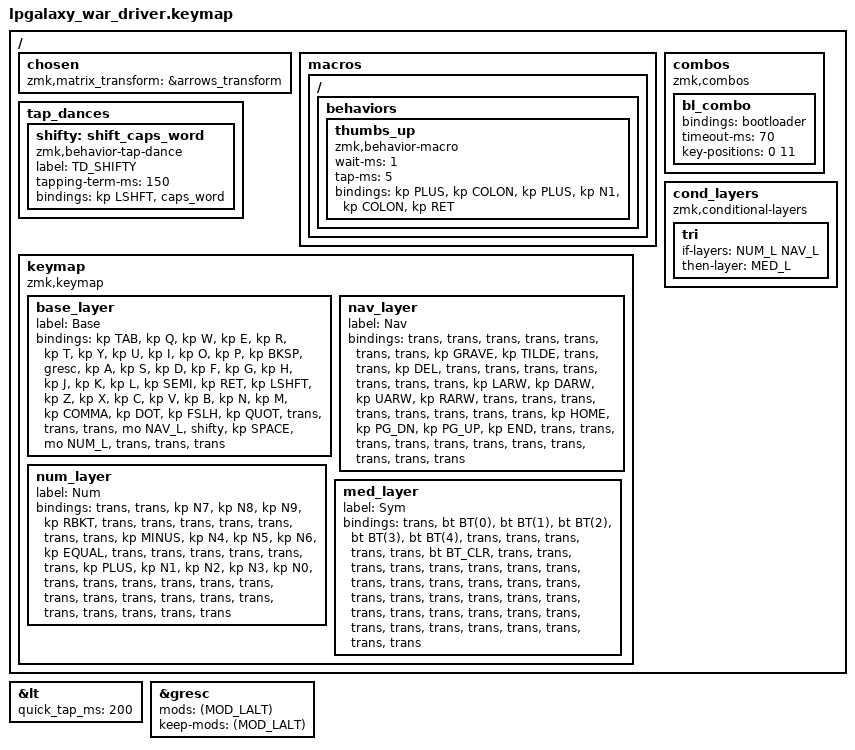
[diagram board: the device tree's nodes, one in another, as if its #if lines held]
/*
 * Copyright (c) 2022 Pete Johanson
 *
 * SPDX-License-Identifier: MIT
 */

#include <behaviors.dtsi>
#include <dt-bindings/zmk/keys.h>
#include <dt-bindings/zmk/bt.h>
#include <dt-bindings/zmk/outputs.h>

// #define QWERTY_BASE 1

#define LAYOUT_STD   1
// #define LAYOUT_ARROWS     1
// #define LAYOUT_SOUTHPAW 1

#define NAV_L 1
#define NUM_L 2
#define MED_L 3

// Using layer taps on thumbs, having quick tap as well helps w/ repeating space/backspace
&lt { quick_tap_ms = <200>; };

#define BT(n) BT_SEL n

&gresc {
    mods = <(MOD_LALT)>;
    keep-mods = <(MOD_LALT)>;
};

/ {
    chosen {
       zmk,matrix_transform =
#ifdef LAYOUT_ARROWS
                       &arrows_transform;
#elif defined(LAYOUT_SOUTHPAW)
                       &southpaw_transform;
#else
                       &standard_transform;
#endif
    };

    macros {
      ZMK_MACRO(thumbs_up,
		wait-ms = <1>;
		tap-ms = <5>;
                bindings = <&kp PLUS &kp COLON &kp PLUS &kp N1 &kp COLON &kp RET>;
		)
    };
    
    tap_dances {
    	shifty: shift_caps_word {
		compatible = "zmk,behavior-tap-dance";
		label = "TD_SHIFTY";
		#binding-cells = <0>;
		tapping-term-ms = <150>;
		bindings = <&kp LSHFT>, <&caps_word>;
	};
    };

    combos {
        compatible = "zmk,combos";
	bl_combo {
		bindings = <&bootloader>;
		timeout-ms = <70>;
		key-positions = <0 11>;
	};
    };

    cond_layers {
        compatible = "zmk,conditional-layers";
	tri {
	    if-layers = <NUM_L NAV_L>;
	    then-layer = <MED_L>;
        };
    };

    keymap {
        compatible = "zmk,keymap";

        base_layer {
            label = "Base";
            bindings = <
#ifdef QWERTY_BASE
 &kp TAB    &kp Q      &kp W      &kp E       &kp R          &kp T          &kp Y            &kp U          &kp I       &kp O      &kp P         &kp BKSP
 &gresc    &kp A      &kp S      &kp D       &kp F          &kp G          &kp H            &kp J          &kp K       &kp L      &kp SEMI      &kp RET
 &kp LSHFT  &kp Z      &kp X      &kp C       &kp V          &kp B          &kp N            &kp M          &kp COMMA   &kp DOT    &kp FSLH      &kp QUOT
#else
 &kp TAB    &kp Q      &kp W      &kp F       &kp P          &kp B   &kp J            &kp L          &kp U       &kp Y      &kp QUOT &kp BKSP
 &gresc    &kp A      &kp R      &kp S       &kp T          &kp G   &kp M            &kp N          &kp E       &kp I      &kp O    &kp RET
 &kp LCTRL  &kp Z      &kp X      &kp C       &kp D          &kp V   &kp K            &kp H          &kp COMMA   &kp DOT    &kp SEMI &kp FSLH
#endif
#ifdef LAYOUT_ARROWS
&trans         &trans &trans    &mo NAV_L      &shifty      &kp SPACE        &mo NUM_L     &trans &trans &trans
#elif defined(LAYOUT_SOUTHPAW)
 &trans &trans         &kp LCTRL  &kp LGUI    &kp LALT          &lt NAV_L SPACE                   &mo NUM_L       &kp RALT &kp RCTRL        &trans &trans
#else
 &kp LGUI         &kp LALT &mo NAV_L        &shifty      &kp SPACE        &mo NUM_L        &kp LALT          &kp RCTL
#endif
            >;
        };

        nav_layer {
            label = "Nav";
            bindings = <
&trans     &trans     &trans     &trans      &trans          &trans       &trans     &kp GRAVE      &kp TILDE   &trans     &trans     &kp DEL
&trans     &trans     &trans     &trans      &trans          &trans       &trans     &kp LARW       &kp DARW    &kp UARW   &kp RARW   &trans
&trans     &trans     &trans     &trans      &trans          &trans       &trans     &kp HOME       &kp PG_DN   &kp PG_UP  &kp END    &trans
#ifdef LAYOUT_ARROWS
&trans  &trans        &trans     &trans              &trans                    &trans       &trans         &trans &trans &trans
#elif defined(LAYOUT_SOUTHPAW)
&trans  &trans        &trans     &trans      &trans                &trans             &trans      &trans   &trans &trans &trans
#else
&trans  &trans        &trans                 &trans       &trans          &trans &trans &trans
#endif
            >;
        };

        num_layer {
            label = "Num";
            bindings = <
&trans     &trans    &kp N7     &kp N8      &kp N9          &kp RBKT     &trans      &trans    &trans     &trans      &trans       &trans
&trans     &kp MINUS &kp N4     &kp N5      &kp N6          &kp EQUAL    &trans      &trans    &trans     &trans      &trans       &trans
&kp PLUS   &kp N1    &kp N2     &kp N3      &kp N0          &trans       &trans      &trans    &trans     &trans      &trans       &trans
#ifdef TBLE_DUAL_2U
&trans  &trans       &trans     &trans              &trans                 &trans            &trans         &trans &trans &trans
#elif defined(TBLE_MIT)
&trans  &trans       &trans     &trans      &trans           &none            &trans        &kp DEL      &trans &trans &trans
#else
&trans  &trans        &trans                 &trans       &trans          &kp ESC &trans &trans
#endif
            >;
        };

        med_layer {
            label = "Sym";
            bindings = <
&trans     &bt BT(0)   &bt BT(1) &bt BT(2)  &bt BT(3)   &bt BT(4)  &trans     &trans    &trans       &trans       &trans     &bt BT_CLR
&trans     &trans      &trans    &trans     &trans      &trans     &trans     &trans    &trans       &trans       &trans     &trans
&trans     &trans      &trans    &trans     &trans      &trans     &trans     &trans    &trans       &trans       &trans     &trans
#ifdef TBLE_DUAL_2U
&trans &trans        &trans     &trans              &trans                    &trans       &trans         &trans &trans &trans
#elif defined(TBLE_MIT)
&trans &trans        &trans     &trans      &trans                &trans             &trans      &trans   &trans &trans &trans
#else
&trans  &trans        &trans                 &trans       &trans          &trans  &trans &trans
#endif
            >;
        };


    };
};

